# FM33LG0XX register map
File version: 1.0
CPU: SC000 r1p0, little endian, no MPU, no FPU, 3 interrupt priority bits
Registers are 32-bit, read-write, reset 0x0 unless marked. A register's access mark holds for its fields unless they carry their own. Offsets are from the block's base; [hi:lo] are bit positions; {n}, {i} and the like mark numbered series.

## CAN — CAN module information
Base 0x40019400
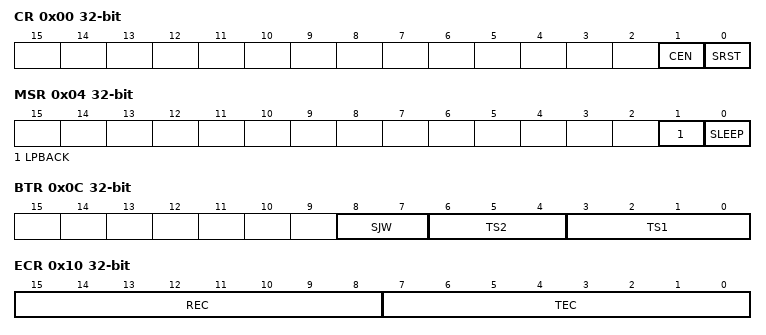
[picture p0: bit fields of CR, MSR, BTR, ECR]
0x00 CR — CAN Control Register
  [1] CEN — CEN field description
  [0] SRST — SRST field description
0x04 MSR — CAN mode select register
  [1] LPBACK — LPBACK field description
  [0] SLEEP — SLEEP field description
0x08 BRPR — CAN Baud rate Prescaler Register
  [7:0] BRP — BRP field description
0x0C BTR — CAN Bit Timing Register
  [8:7] SJW — SJW field description
  [6:4] TS2 — TS2 field description
  [3:0] TS1 — TS1 field description
0x10 ECR ro — CAN Error Counter Register
  [15:8] REC — REC field description
  [7:0] TEC — TEC field description
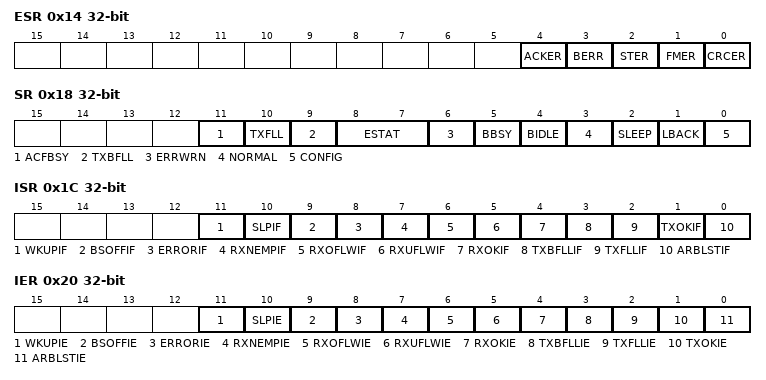
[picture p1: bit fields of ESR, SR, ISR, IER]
0x14 ESR — CAN Error Status Register
  [4] ACKER — ACKER field description
  [3] BERR — BERR field description
  [2] STER — STER field description
  [1] FMER — FMER field description
  [0] CRCER — CRCER field description
0x18 SR ro — CAN Status Register
  [11] ACFBSY — ACFBSY field description
  [10] TXFLL — TXFLL field description
  [9] TXBFLL — TXBFLL field description
  [8:7] ESTAT — ESTAT field description
  [6] ERRWRN — ERRWRN field description
  [5] BBSY — BBSY field description
  [4] BIDLE — BIDLE field description
  [3] NORMAL — NORMAL field description
  [2] SLEEP — SLEEP field description
  [1] LBACK — LBACK field description
  [0] CONFIG — CONFIG field description
0x1C ISR ro — CAN Interrupt Status Register
  [11] WKUPIF — WKUPIF field description
  [10] SLPIF — SLPIF field description
  [9] BSOFFIF — BSOFFIF field description
  [8] ERRORIF — ERRORIF field description
  [7] RXNEMPIF — RXNEMPIF field description
  [6] RXOFLWIF — RXOFLWIF field description
  [5] RXUFLWIF — RXUFLWIF field description
  [4] RXOKIF — RXOKIF field description
  [3] TXBFLLIF — TXBFLLIF field description
  [2] TXFLLIF — TXFLLIF field description
  [1] TXOKIF — TXOKIF field description
  [0] ARBLSTIF — ARBLSTIF field description
0x20 IER — CAN Interrupt Enable Register
  [11] WKUPIE — WKUPIE field description
  [10] SLPIE — SLPIE field description
  [9] BSOFFIE — BSOFFIE field description
  [8] ERRORIE — ERRORIE field description
  [7] RXNEMPIE — RXNEMPIE field description
  [6] RXOFLWIE — RXOFLWIE field description
  [5] RXUFLWIE — RXUFLWIE field description
  [4] RXOKIE — RXOKIE field description
  [3] TXBFLLIE — TXBFLLIE field description
  [2] TXFLLIE — TXFLLIE field description
  [1] TXOKIE — TXOKIE field description
  [0] ARBLSTIE — ARBLSTIE field description
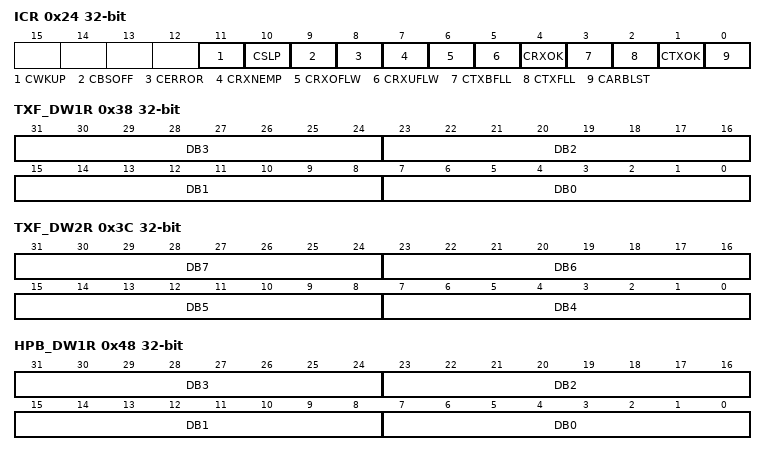
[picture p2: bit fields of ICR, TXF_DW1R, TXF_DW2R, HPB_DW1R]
0x24 ICR — CAN Interrupt Clear Register
  [11] CWKUP — CWKUP field description
  [10] CSLP — CSLP field description
  [9] CBSOFF — CBSOFF field description
  [8] CERROR — CERROR field description
  [7] CRXNEMP — CRXNEMP field description
  [6] CRXOFLW — CRXOFLW field description
  [5] CRXUFLW — CRXUFLW field description
  [4] CRXOK — CRXOK field description
  [3] CTXBFLL — CTXBFLL field description
  [2] CTXFLL — CTXFLL field description
  [1] CTXOK — CTXOK field description
  [0] CARBLST — CARBLST field description
0x30 TXF_IDR wo — CAN TX FIFO ID Register
  [31:0] IDR — IDR field description
0x34 TXF_DLCR wo — CAN TX FIFO DLC Register
  [3:0] DLC — DLC field description
0x38 TXF_DW1R wo — CAN TX FIFO Data Word1 Register
  [8n+7:8n] DB{n} (n=0..3) — DB{n} field description
0x3C TXF_DW2R wo — CAN TX FIFO Data Word2 Register
  [8n-25:8n-32] DB{n} (n=4..7) — DB{n} field description
0x40 HPB_IDR wo — CAN TX HPB ID Register
  [31:0] IDR — IDR field description
0x44 HPB_DLCR wo — CAN TX HPB DLC Register
  [3:0] DLC — DLC field description
0x48 HPB_DW1R wo — CAN TX HPB Data Word1 Register
  [8n+7:8n] DB{n} (n=0..3) — DB{n} field description
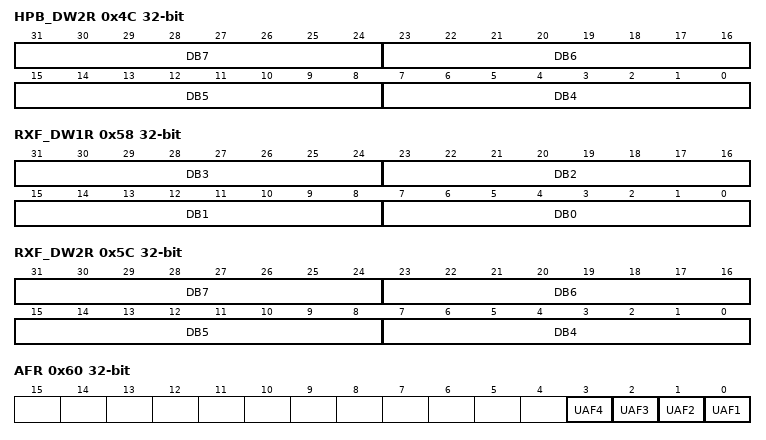
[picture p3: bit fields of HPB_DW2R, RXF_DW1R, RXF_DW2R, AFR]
0x4C HPB_DW2R wo — CAN TX HPB Data Word2 Register
  [8n-25:8n-32] DB{n} (n=4..7) — DB{n} field description
0x50 RXF_IDR wo — CAN RX FIFO ID Register
  [31:0] IDR — IDR field description
0x54 RXF_DLCR wo — CAN RX FIFO DLC Register
  [3:0] DLC — DLC field description
0x58 RXF_DW1R wo — CAN RX FIFO Data Word1 Register
  [8n+7:8n] DB{n} (n=0..3) — DB{n} field description
0x5C RXF_DW2R wo — CAN RX FIFO Data Word2 Register
  [8n-25:8n-32] DB{n} (n=4..7) — DB{n} field description
0x60 AFR — Acceptance Filter Register
  [n-1] UAF{n} (n=1..4) — UAF{n} field description
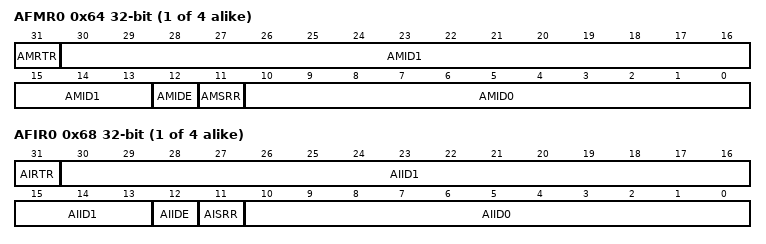
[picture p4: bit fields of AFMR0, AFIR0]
{0x64+8i} AFMR{i} (i=0..3) — Acceptance Filter Mask Register{i+1}
  [31] AMRTR — AMRTR field description
  [30:13] AMID1 — AMID1 field description
  [12] AMIDE — AMIDE field description
  [11] AMSRR — AMSRR field description
  [10:0] AMID0 — AMID0 field description
{0x68+8i} AFIR{i} (i=0..3) — Acceptance Filter ID Register{i+1}
  [31] AIRTR — AIRTR field description
  [30:13] AIID1 — AIID1 field description
  [12] AIIDE — AIIDE field description
  [11] AISRR — AISRR field description
  [10:0] AIID0 — AIID0 field description
